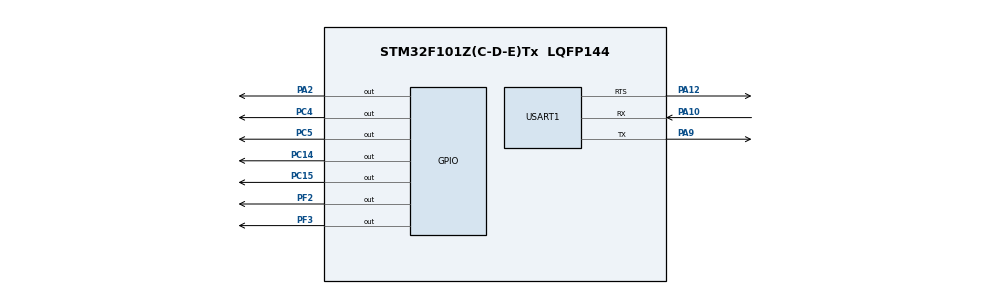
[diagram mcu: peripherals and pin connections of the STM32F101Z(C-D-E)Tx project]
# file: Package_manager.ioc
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Dma.Request0=USART1_RX
Dma.Request1=USART1_TX
Dma.USART1_RX.0.Direction=DMA_PERIPH_TO_MEMORY
Dma.USART1_RX.0.Instance=DMA1_Channel5
Dma.USART1_RX.0.MemDataAlignment=DMA_MDATAALIGN_BYTE
Dma.USART1_RX.0.MemInc=DMA_MINC_ENABLE
Dma.USART1_RX.0.Mode=DMA_NORMAL
Dma.USART1_RX.0.PeriphDataAlignment=DMA_PDATAALIGN_BYTE
Dma.USART1_RX.0.PeriphInc=DMA_PINC_DISABLE
Dma.USART1_RX.0.Priority=DMA_PRIORITY_LOW
Dma.USART1_TX.1.Direction=DMA_MEMORY_TO_PERIPH
Dma.USART1_TX.1.Instance=DMA1_Channel4
Dma.USART1_TX.1.MemDataAlignment=DMA_MDATAALIGN_BYTE
Dma.USART1_TX.1.MemInc=DMA_MINC_ENABLE
Dma.USART1_TX.1.Mode=DMA_NORMAL
Dma.USART1_TX.1.PeriphDataAlignment=DMA_PDATAALIGN_BYTE
Dma.USART1_TX.1.PeriphInc=DMA_PINC_DISABLE
Dma.USART1_TX.1.Priority=DMA_PRIORITY_LOW
Mcu.Family=STM32F1
Mcu.Name=STM32F101Z(C-D-E)Tx
Mcu.Package=LQFP144
NVIC.DMA1_Channel4_IRQn=true\:0\:0\:false\:false\:true
NVIC.DMA1_Channel5_IRQn=true\:0\:0\:false\:false\:true
NVIC.PriorityGroup=NVIC_PRIORITYGROUP_4
NVIC.TIM7_IRQn=true\:0\:0\:false\:false\:true
NVIC.USART1_IRQn=true\:0\:0\:false\:false\:true
OSC_IN.Mode=HSE-External-Oscillator
OSC_IN.Signal=RCC_OSC_IN
OSC_OUT.Mode=HSE-External-Oscillator
OSC_OUT.Signal=RCC_OSC_OUT
PA10.Mode=Asynchronous
PA10.Signal=USART1_RX
PA12.Mode=RTS_Only
PA12.Signal=USART1_RTS
PA2.Signal=GPIO_Output
PA9.Mode=Asynchronous
PA9.Signal=USART1_TX
PC14-OSC32_IN.Signal=GPIO_Output
PC15-OSC32_OUT.Signal=GPIO_Output
PC4.Signal=GPIO_Output
PC5.Signal=GPIO_Output
PF2.Signal=GPIO_Output
PF3.Signal=GPIO_Output
ProjectManager.HeapSize=0x200
ProjectManager.StackSize=0x400
ProjectManager.TargetToolchain=MDK-ARM V5
RCC.APB1Freq_Value=8000000
RCC.APB2Freq_Value=8000000
RCC.ClockTypeHCLK=RCC_CLOCKTYPE_HCLK
RCC.ClockTypePCLK1=RCC_CLOCKTYPE_PCLK1
RCC.ClockTypePCLK2=RCC_CLOCKTYPE_PCLK2
RCC.EnableHSE=true
RCC.EnableHSERTCDevisor=false
RCC.EnableLSE=false
RCC.EnableLSERTC=false
RCC.EnableMCOMultDivisor=false
RCC.HSEState=RCC_HSE_ON
RCC.HSIState=RCC_HSI_ON
RCC.IWDGEnable=false
RCC.LSIState=RCC_LSI_OFF
RCC.MCOEnable=false
RCC.OscillatorTypeHSI=RCC_OSCILLATORTYPE_HSI
RCC.PLLSource=RCC_PLLSOURCE_HSI_DIV2
RCC.PLLSourceVirtual=RCC_PLLSOURCE_HSI_DIV2
RCC.PLLState=RCC_PLL_OFF
RCC.RTCEnable=false
TIM7.Period=2000
TIM7.Prescaler=8000
TIM7.TIM_MasterSlaveMode=TIM_MASTERSLAVEMODE_DISABLE
USART1.HwFlowCtl-Asynchronous=UART_HWCONTROL_RTS
USART1.HwFlowCtl-RTS_Only=UART_HWCONTROL_RTS
USART1.VirtualMode=VM_ASYNC
VP_SYS_VS_ND.Mode=No_Debug
VP_TIM7_VS_ClockSourceINT.Mode=Enable_Timer
board=Package_manager

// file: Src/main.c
/**
  ******************************************************************************
  * File Name          : main.c
  * Description        : Main program body
  ******************************************************************************
  *
  * COPYRIGHT(c) 2017 STMicroelectronics
  *
  * Redistribution and use in source and binary forms, with or without modification,
  * are permitted provided that the following conditions are met:
  *   1. Redistributions of source code must retain the above copyright notice,
  *      this list of conditions and the following disclaimer.
  *   2. Redistributions in binary form must reproduce the above copyright notice,
  *      this list of conditions and the following disclaimer in the documentation
  *      and/or other materials provided with the distribution.
  *   3. Neither the name of STMicroelectronics nor the names of its contributors
  *      may be used to endorse or promote products derived from this software
  *      without specific prior written permission.
  *
  * THIS SOFTWARE IS PROVIDED BY THE COPYRIGHT HOLDERS AND CONTRIBUTORS "AS IS"
  * AND ANY EXPRESS OR IMPLIED WARRANTIES, INCLUDING, BUT NOT LIMITED TO, THE
  * IMPLIED WARRANTIES OF MERCHANTABILITY AND FITNESS FOR A PARTICULAR PURPOSE ARE
  * DISCLAIMED. IN NO EVENT SHALL THE COPYRIGHT HOLDER OR CONTRIBUTORS BE LIABLE
  * FOR ANY DIRECT, INDIRECT, INCIDENTAL, SPECIAL, EXEMPLARY, OR CONSEQUENTIAL
  * DAMAGES (INCLUDING, BUT NOT LIMITED TO, PROCUREMENT OF SUBSTITUTE GOODS OR
  * SERVICES; LOSS OF USE, DATA, OR PROFITS; OR BUSINESS INTERRUPTION) HOWEVER
  * CAUSED AND ON ANY THEORY OF LIABILITY, WHETHER IN CONTRACT, STRICT LIABILITY,
  * OR TORT (INCLUDING NEGLIGENCE OR OTHERWISE) ARISING IN ANY WAY OUT OF THE USE
  * OF THIS SOFTWARE, EVEN IF ADVISED OF THE POSSIBILITY OF SUCH DAMAGE.
  *
  ******************************************************************************
  */
#include "main.h"
#include "stm32f1xx_hal.h"

/* USER CODE BEGIN Includes */
#include "drv_command.h"
#include "drv_lock.h"

#define LOCKS_NUM										12 				//Number of locks on each PCB
struct locks locks_array[LOCKS_NUM];

/* USER CODE END Includes */

TIM_HandleTypeDef htim7;

UART_HandleTypeDef huart1;
DMA_HandleTypeDef hdma_usart1_rx;
DMA_HandleTypeDef hdma_usart1_tx;

/* USER CODE BEGIN PV */
/* Private variables ---------------------------------------------------------*/

/* USER CODE END PV */

void SystemClock_Config(void);
void Error_Handler(void);
static void MX_GPIO_Init(void);
static void MX_DMA_Init(void);
static void MX_TIM7_Init(void);
static void MX_USART1_UART_Init(void);

/* USER CODE BEGIN PFP */
/* Private function prototypes -----------------------------------------------*/

/* USER CODE END PFP */

int main(void)
{

  /* MCU Configuration----------------------------------------------------------*/

  /* Reset of all peripherals, Initializes the Flash interface and the Systick. */
  HAL_Init();

  /* Configure the system clock */
  SystemClock_Config();

  /* Initialize all configured peripherals */
  MX_GPIO_Init();
  MX_DMA_Init();
  MX_TIM7_Init();
  MX_USART1_UART_Init();

  /* USER CODE BEGIN 2 */

	HAL_TIM_Base_Start_IT(&htim7);

	locksInit(locks_array);

	HAL_GPIO_WritePin(locks_array[0].port[0], locks_array[0].pin[0], GPIO_PIN_SET);
	HAL_GPIO_WritePin(locks_array[0].port[1], locks_array[0].pin[1], GPIO_PIN_RESET);

//	HAL_GPIO_WritePin(GPIOC, GPIO_PIN_14, GPIO_PIN_SET);
//	HAL_GPIO_WritePin(GPIOC, GPIO_PIN_15, GPIO_PIN_RESET);
  /* USER CODE END 2 */

  /* Infinite loop */
  while (1)
  {

  }

}

/** System Clock Configuration
*/
void SystemClock_Config(void)
{

  RCC_OscInitTypeDef RCC_OscInitStruct;
  RCC_ClkInitTypeDef RCC_ClkInitStruct;

    /**Initializes the CPU, AHB and APB busses clocks
    */
  RCC_OscInitStruct.OscillatorType = RCC_OSCILLATORTYPE_HSI;
  RCC_OscInitStruct.HSIState = RCC_HSI_ON;
  RCC_OscInitStruct.HSICalibrationValue = 16;
  RCC_OscInitStruct.PLL.PLLState = RCC_PLL_NONE;
  if (HAL_RCC_OscConfig(&RCC_OscInitStruct) != HAL_OK)
  {
    Error_Handler();
  }

    /**Initializes the CPU, AHB and APB busses clocks
    */
  RCC_ClkInitStruct.ClockType = RCC_CLOCKTYPE_HCLK|RCC_CLOCKTYPE_SYSCLK
                              |RCC_CLOCKTYPE_PCLK1|RCC_CLOCKTYPE_PCLK2;
  RCC_ClkInitStruct.SYSCLKSource = RCC_SYSCLKSOURCE_HSI;
  RCC_ClkInitStruct.AHBCLKDivider = RCC_SYSCLK_DIV1;
  RCC_ClkInitStruct.APB1CLKDivider = RCC_HCLK_DIV1;
  RCC_ClkInitStruct.APB2CLKDivider = RCC_HCLK_DIV1;

  if (HAL_RCC_ClockConfig(&RCC_ClkInitStruct, FLASH_LATENCY_0) != HAL_OK)
  {
    Error_Handler();
  }

    /**Configure the Systick interrupt time
    */
  HAL_SYSTICK_Config(HAL_RCC_GetHCLKFreq()/1000);

    /**Configure the Systick
    */
  HAL_SYSTICK_CLKSourceConfig(SYSTICK_CLKSOURCE_HCLK);

  /* SysTick_IRQn interrupt configuration */
  HAL_NVIC_SetPriority(SysTick_IRQn, 0, 0);
}

/* TIM7 init function */
static void MX_TIM7_Init(void)
{

  TIM_MasterConfigTypeDef sMasterConfig;

  htim7.Instance = TIM7;
  htim7.Init.Prescaler = 8000;
  htim7.Init.CounterMode = TIM_COUNTERMODE_UP;
  htim7.Init.Period = 2000;
  if (HAL_TIM_Base_Init(&htim7) != HAL_OK)
  {
    Error_Handler();
  }

  sMasterConfig.MasterOutputTrigger = TIM_TRGO_RESET;
  sMasterConfig.MasterSlaveMode = TIM_MASTERSLAVEMODE_DISABLE;
  if (HAL_TIMEx_MasterConfigSynchronization(&htim7, &sMasterConfig) != HAL_OK)
  {
    Error_Handler();
  }

}

/* USART1 init function */
static void MX_USART1_UART_Init(void)
{

  huart1.Instance = USART1;
  huart1.Init.BaudRate = 115200;
  huart1.Init.WordLength = UART_WORDLENGTH_8B;
  huart1.Init.StopBits = UART_STOPBITS_1;
  huart1.Init.Parity = UART_PARITY_NONE;
  huart1.Init.Mode = UART_MODE_TX_RX;
  huart1.Init.HwFlowCtl = UART_HWCONTROL_RTS;
  huart1.Init.OverSampling = UART_OVERSAMPLING_16;
  if (HAL_UART_Init(&huart1) != HAL_OK)
  {
    Error_Handler();
  }

}

static void MX_DMA_Init(void)
{
  /* DMA controller clock enable */
  __HAL_RCC_DMA1_CLK_ENABLE();

  /* DMA interrupt init */
  /* DMA1_Channel4_IRQn interrupt configuration */
  HAL_NVIC_SetPriority(DMA1_Channel4_IRQn, 0, 0);
  HAL_NVIC_EnableIRQ(DMA1_Channel4_IRQn);
  /* DMA1_Channel5_IRQn interrupt configuration */
  HAL_NVIC_SetPriority(DMA1_Channel5_IRQn, 0, 0);
  HAL_NVIC_EnableIRQ(DMA1_Channel5_IRQn);

}

/** Configure pins as
        * Analog
        * Input
        * Output
        * EVENT_OUT
        * EXTI
*/
static void MX_GPIO_Init(void)
{

  GPIO_InitTypeDef GPIO_InitStruct;

  /* GPIO Ports Clock Enable */
  __HAL_RCC_GPIOC_CLK_ENABLE();
  __HAL_RCC_GPIOF_CLK_ENABLE();
  __HAL_RCC_GPIOA_CLK_ENABLE();

  /*Configure GPIO pin Output Level */
  HAL_GPIO_WritePin(GPIOC, GPIO_PIN_14|GPIO_PIN_15|GPIO_PIN_4|GPIO_PIN_5, GPIO_PIN_RESET);

  /*Configure GPIO pin Output Level */
  HAL_GPIO_WritePin(GPIOF, GPIO_PIN_2|GPIO_PIN_3, GPIO_PIN_RESET);

  /*Configure GPIO pin Output Level */
  HAL_GPIO_WritePin(GPIOA, GPIO_PIN_2, GPIO_PIN_RESET);

  /*Configure GPIO pins : PC14 PC15 PC4 PC5 */
  GPIO_InitStruct.Pin = GPIO_PIN_14|GPIO_PIN_15|GPIO_PIN_4|GPIO_PIN_5;
  GPIO_InitStruct.Mode = GPIO_MODE_OUTPUT_PP;
  GPIO_InitStruct.Speed = GPIO_SPEED_FREQ_LOW;
  HAL_GPIO_Init(GPIOC, &GPIO_InitStruct);

  /*Configure GPIO pins : PF2 PF3 */
  GPIO_InitStruct.Pin = GPIO_PIN_2|GPIO_PIN_3;
  GPIO_InitStruct.Mode = GPIO_MODE_OUTPUT_PP;
  GPIO_InitStruct.Speed = GPIO_SPEED_FREQ_LOW;
  HAL_GPIO_Init(GPIOF, &GPIO_InitStruct);

  /*Configure GPIO pin : PA2 */
  GPIO_InitStruct.Pin = GPIO_PIN_2;
  GPIO_InitStruct.Mode = GPIO_MODE_OUTPUT_PP;
  GPIO_InitStruct.Speed = GPIO_SPEED_FREQ_LOW;
  HAL_GPIO_Init(GPIOA, &GPIO_InitStruct);

}

void Error_Handler(void)
{
  while(1)
  {
  }
}

/************************ (C) COPYRIGHT STMicroelectronics *****END OF FILE****/
